VERSION ""

NS_ :

BS_:

BU_:

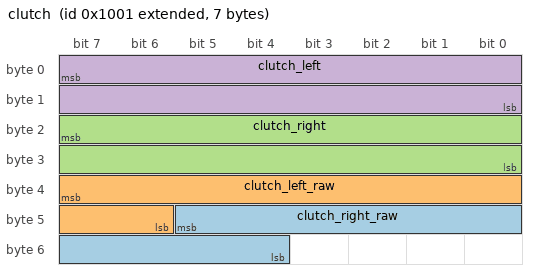
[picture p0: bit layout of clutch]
BO_ 2147487745 clutch: 7 Vector__XXX
 SG_ clutch_right_raw : 45|10@0+ (1,0) [0|0] "" Vector__XXX
 SG_ clutch_left_raw : 39|10@0+ (1,0) [0|0] "" Vector__XXX
 SG_ clutch_right : 23|16@0+ (0.01,0) [0|100] "%" Vector__XXX
 SG_ clutch_left : 7|16@0+ (0.01,0) [0|100] "%" Vector__XXX

BA_DEF_ BO_  "GenMsgCycleTime" INT 0 65535;
BA_DEF_DEF_  "GenMsgCycleTime" 0;
BA_ "GenMsgCycleTime" BO_ 2147487745 10;
